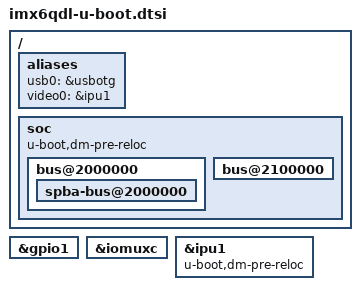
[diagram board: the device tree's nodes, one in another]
// SPDX-License-Identifier: GPL-2.0+
/*
 * Copyright (C) 2018 Jagan Teki <jagan@amarulasolutions.com>
 */

/ {
	aliases {
		usb0 = &usbotg;
		video0 = &ipu1;
	};

	soc {
		u-boot,dm-spl;
		u-boot,dm-pre-reloc;

		bus@2000000 {
			u-boot,dm-spl;
			spba-bus@2000000 {
				u-boot,dm-spl;
			};
		};

		bus@2100000 {
			u-boot,dm-spl;
		};
	};
};

&gpio1 {
	u-boot,dm-spl;
};

&iomuxc {
	u-boot,dm-spl;
};

&ipu1 {
	u-boot,dm-pre-reloc;
};
